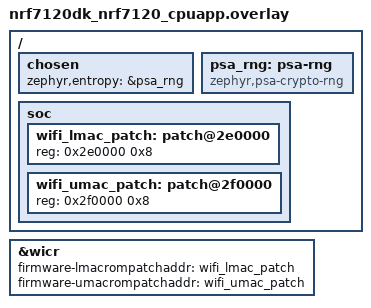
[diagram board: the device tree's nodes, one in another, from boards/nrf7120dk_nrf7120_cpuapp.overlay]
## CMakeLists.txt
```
#
# Copyright (c) 2026 Nordic Semiconductor ASA
#
# SPDX-License-Identifier: LicenseRef-Nordic-5-Clause
#

cmake_minimum_required(VERSION 3.20.0)

# The WICR LMAC/UMAC ROM patch addresses must point at the patch regions, or
# the RPU boots unpatched ROM, which has no CM2CD command handling. The dtsi
# must match the patch selected through WIFI_NRF71_PATCH_VERSION. Do not also
# pass a patch dtsi through EXTRA_DTC_OVERLAY_FILE.
list(APPEND EXTRA_DTC_OVERLAY_FILE
     ${CMAKE_CURRENT_LIST_DIR}/../../../../nrfxlib/nrf71_wifi/bins/0.1.0/nrf7120_wifi_patch.dtsi)

find_package(Zephyr REQUIRED HINTS $ENV{ZEPHYR_BASE})
project(nrf71_sr_coex)

target_sources(app PRIVATE
  src/main.c
  src/coex_tb_util.c
  src/coex_tb_params.c
  src/coex_tb_stats.c
  src/coex_tb_tests.c
)

target_include_directories(app PRIVATE
  ${ZEPHYR_NRF_MODULE_DIR}/drivers/nrf71_sr_coex/include
  ${ZEPHYR_NRF_MODULE_DIR}/drivers/wifi/nrf71/fw_if
  ${ZEPHYR_NRF_MODULE_DIR}/drivers/wifi/nrf71/osal/hw_if/hal/inc
  ${ZEPHYR_NRF_MODULE_DIR}/drivers/wifi/nrf71/inc
  ${ZEPHYR_NRF_MODULE_DIR}/drivers/wifi/nrf71/inc/common/fw_if
)
```

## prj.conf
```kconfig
# Copyright (c) 2026 Nordic Semiconductor ASA
#
# SPDX-License-Identifier: LicenseRef-Nordic-5-Clause
#

# The Wi-Fi and Short-Range coexistence driver under test.
CONFIG_NRF71_SR_COEX_DRIVER=y

# The coexistence driver sits between: the nRF71 Wi-Fi driver owns
# the FMAC transport that carries CD2CM commands to the RPU, and
# the Short-Range (for example, Bluetooth) side of the arbitration.
CONFIG_WIFI=y
CONFIG_WIFI_NM_WPA_SUPPLICANT=y
CONFIG_BT=y

# The Coexistence Manager command handling lives in the Wi-Fi ROM patch. The
# board overlay points WICR at the patch regions, so the patch must be merged
# into the flashed image.
CONFIG_WIFI_NRF71_PATCH=y

# bt_le_set_chan_map() returns -ENOTSUP unless the Controller is a central or a
# broadcaster, so the BLE bad-channel mapping test needs one of the two roles.
CONFIG_BT_CENTRAL=y

# Networking (Wi-Fi driver build dependency).
CONFIG_NETWORKING=y
CONFIG_NET_L2_ETHERNET=y
CONFIG_NET_L2_ETHERNET_MGMT=y
CONFIG_NET_MGMT=y
CONFIG_NET_MGMT_EVENT=y

CONFIG_NET_PKT_RX_COUNT=16
CONFIG_NET_PKT_TX_COUNT=16
CONFIG_NET_BUF_RX_COUNT=16
CONFIG_NET_BUF_TX_COUNT=32
CONFIG_HEAP_MEM_POOL_SIZE=230000

# IPC transport to the RPU.
CONFIG_IPC_SERVICE_BACKEND_ICMSG_WQ_ENABLE=y
CONFIG_IPC_SERVICE_BACKEND_ICMSG_WQ_STACK_SIZE=5600

# Logging. Immediate mode keeps driver log lines interleaved with the test
# bench printk output in the right order, which matters when reading a failure.
CONFIG_LOG=y
CONFIG_LOG_MODE_IMMEDIATE=y
CONFIG_NRF71_SR_COEX_DRIVER_LOG_LEVEL_DBG=y

# Keep the Wi-Fi driver debug logging off so it does not bury the test bench output.
CONFIG_WIFI_NRF71_LOG_LEVEL_DBG=n

# Set to y to open an MPC override on the Wi-Fi debug register window
# (0x48000000) so a debugger can reach the LMAC/UMAC VPRs. Useful to tell "Wi-Fi
# core never started" apart from "core runs but the ipc0 ICMsg peer never binds",
# because nrf_wifi_fmac_ver_get() is stubbed and its "booted successfully" log
# line does not touch the RPU. Disabled by default.
CONFIG_SOC_NRF71_WIFI_DAP=n

CONFIG_MAIN_STACK_SIZE=8192
```

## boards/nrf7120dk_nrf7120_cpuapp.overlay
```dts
/*
 * Copyright (c) 2026 Nordic Semiconductor ASA
 *
 * SPDX-License-Identifier: LicenseRef-Nordic-5-Clause
 */

/* Enable PSA RNG for entropy */
/ {
	chosen {
		zephyr,entropy = &psa_rng;
	};

	psa_rng: psa-rng {
		compatible = "zephyr,psa-crypto-rng";
		status = "okay";
	};
};

/*
 * The LMAC and UMAC ROM patch descriptors sit in MRAM: LMAC_APP.hex populates
 * 0x2e0000 and UMAC_APP.hex populates 0x2f0000, which is also what
 * nrfxlib/nrf71_wifi/bins/wicr.hex points the WICR patch words at.
 *
 * nrf7120_enga.dtsi instead points firmware-lmacrompatchaddr and
 * firmware-umacrompatchaddr at the ROM entry offsets (0x28080172 / 0x2818011c),
 * so wicr_setup() overwrites the flashed patch addresses at boot and the ROM
 * follows a bogus pointer, leaving the Wi-Fi core dead before IPC init.
 */
/ {
	soc {
		wifi_lmac_patch: patch@2e0000 {
			reg = <0x2e0000 0x8>;
		};

		wifi_umac_patch: patch@2f0000 {
			reg = <0x2f0000 0x8>;
		};
	};
};

&wicr {
	firmware-lmacrompatchaddr = <&wifi_lmac_patch>;
	firmware-umacrompatchaddr = <&wifi_umac_patch>;
};
```

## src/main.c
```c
/* main.c - build-only exercise of the nRF71 SR coexistence driver API */

/*
 * Copyright (c) 2026 Nordic Semiconductor ASA
 *
 * SPDX-License-Identifier: LicenseRef-Nordic-5-Clause
 */

#include <errno.h>

#include <zephyr/kernel.h>
#include <zephyr/sys/printk.h>

#include <drivers/nrf71_sr_coex/nrf71_sr_coex.h>
#include <drivers/nrf71_sr_coex/nrf71_sr_coex_sr.h>

/*
 * This test builds the standalone nRF71 SR coexistence driver together with the
 * nRF71 Wi-Fi driver and exercises the driver API contract so the driver links
 * against the Wi-Fi FMAC coexistence transport. It also registers stub
 * Short-Range driver callbacks, as the real SR driver does at boot.
 */
static int test_sr_enable(bool enable)
{
	ARG_UNUSED(enable);
	return 0;
}

static int test_sr_set_priority(const struct nrf71_sr_coex_sr_prio *prio)
{
	ARG_UNUSED(prio);
	return 0;
}

static const struct nrf71_sr_coex_sr_driver_cb test_sr_driver_cb = {
	.enable = test_sr_enable,
	.set_priority = test_sr_set_priority,
};

int main(void)
{
	const struct nrf71_sr_coex_prio prio = {
		.wifi = {
			.sw_request = {10, 5, 1},
			.hp_rx = {20, 15, 1},
			.hp_tx = {25, 20, 1},
			.lp_rx = {140, 120, 3},
			.lp_tx = {160, 145, 3},
			.level = 5,
		},
		.sr = {
			.rx = {30, 25, 1},
			.tx = {40, 30, 2},
			.rx_critical = {5, 0, 1},
			.tx_critical = {5, 0, 1},
			.level = 5,
		},
	};
	const struct nrf71_sr_coex_user_params user = {
		.sr_rx_prot_ps_listen2inactive = 100,
		.sr_rx_prot_ps_inactive2listen = 100,
		.sr_rx_prot_calib_listen2inactive = 100,
		.sr_rx_prot_calib_inactive2listen = 100,
		.wifi_scan_prot = 100,
		.wifi_beacon_prot = 100,
		.wifi_conn_prot = 100,
		.wifi_calib_prot = 100,
		.ant_alloc = NRF71_SR_COEX_ANT_ALLOC_DYNAMIC,
	};
	const struct nrf71_sr_coex_cfg cfg = {
		.antenna = NRF71_SR_COEX_ANTENNA_SHARED,
		.prio = &prio,
		.user = &user,
	};
	int ret;

	ret = nrf71_sr_coex_sr_register(&test_sr_driver_cb);
	if (ret != 0) {
		printk("SR driver callback registration failed: %d\n", ret);
	}

	(void)nrf71_sr_coex_sr_power_notify(NRF71_SR_COEX_SR_POWERED_UP_READY);
	(void)nrf71_sr_coex_sr_power_notify(NRF71_SR_COEX_SR_PREPARE_POWER_DOWN);

	/*
	 * The priority ranges and user params are stored whether Wi-Fi is up or
	 * not, and applied to the CM every time Wi-Fi comes up, so this succeeds.
	 */
	ret = nrf71_sr_coex_init(&cfg);
	printk("nrf71_sr_coex_init(): %d (expected 0)\n", ret);

	/* The configuration can be set only once. */
	ret = nrf71_sr_coex_init(&cfg);
	printk("nrf71_sr_coex_init() twice: %d (expected %d)\n", ret, -EALREADY);

	printk("nRF71 SR coexistence driver built\n");

	return 0;
}
```

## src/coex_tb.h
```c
/*
 * Copyright (c) 2026 Nordic Semiconductor ASA
 *
 * SPDX-License-Identifier: LicenseRef-Nordic-5-Clause
 */

/** @file
 * @brief nRF71 SR coexistence driver test bench configuration.
 *
 * The bench exercises the driver's interfaces:
 *
 *   1. Application / configuration APIs (coex_cd_*). These turn into CD2CM commands.
 *   2. Wi-Fi driver to CD notifications (coex_cd_wifi_power_notify, which drives
 *      the driver's CM bring-up and teardown sequence, and
 *      coex_cd_wifi_channel_notify, which drives BLE bad-channel mapping).
 *   3. SR driver to CD notifications (coex_cd_sr_power_notify) and the SR driver
 *      callbacks the SR driver registers through coex_cd_register_sr_driver_cb().
 *   4. Direct COEXC hardware programming which is register access rather than messaging.
 *
 * TEST ORDER MATTERS
 * ------------------
 * The steps below are not independent. COEXC hardware must be programmed before
 * CM arbitration has any effect, and both radios must report "powered up" before
 * CM-dependent steps run.
 *
 * CM bring-up: coex_tb_prepare() calls coex_cd_wifi_power_notify() automatically
 * when any CM-dependent test is enabled and COEX_TB_TEST_INIT_AND_ENABLE is not. Enable
 * COEX_TB_TEST_INIT_AND_ENABLE only when you want to exercise that notification
 * API explicitly.
 */

#ifndef COEX_TB_H__
#define COEX_TB_H__

#include <stdint.h>

#include <nrf71_coex_if.h>
#include <nrf71_sr_coex_api.h>

/* Timing (all values in milliseconds) */
/** Pause after a command whose effect needs a moment to be observable. */
#define COEX_TB_CMD_WAIT_MS            500U

/** Final drain time before the verdict is printed. */
#define COEX_TB_FINAL_WAIT_MS          2000U

/** Interval between polls while waiting for the Wi-Fi FMAC transport. */
#define COEX_TB_POLL_INTERVAL_MS       100U

/** Consecutive ready polls required before the transport is trusted. */
#define COEX_TB_TRANSPORT_STABLE_POLLS 5U

/** Extra time after transport looks ready, before CM commands (RPU/VIF settle). */
#define COEX_TB_RPU_SETTLE_MS          3000U

/** How long to wait for Wi-Fi-driver CM bring-up before retrying from the bench. */
#define COEX_TB_CM_BRINGUP_TIMEOUT_MS  30000U

/** Give up waiting for the Wi-Fi transport after this long. */
#define COEX_TB_TRANSPORT_TIMEOUT_MS   60000U

/*
 * ---------------------------------------------------------------------------
 * Buffer sizes and blob layout
 * ---------------------------------------------------------------------------
 */

/**
 * Size of the CD2CM_UPDATE_COEX_PARAMS blob buffer.
 *
 * Taken straight from the driver's advertised limit, CD2CM_COEX_PARAMS_MAX_BLOB_LEN
 * in nrf71_sr_coex_api.h.
 */
#define COEX_TB_COEX_PARAMS_BLOB_MAX CD2CM_COEX_PARAMS_MAX_BLOB_LEN

/**
 * Byte offset of the shared-LNA-switch control field inside the decoded
 * NRF_COEX_PARAMS blob.
 */
#define COEX_TB_BLOB_LNASW_OFFSET 44U

/**
 * Print the Wi-Fi core bring-up state (WICR words and ipc0 regions) before the test
 * run starts. Diagnostic for a Wi-Fi transport that never comes up. Comment out to
 * skip it.
 */
#define COEX_TB_DUMP_WIFI_BRINGUP_STATE

/*
 * ---------------------------------------------------------------------------
 * Test selection: comment out a line to skip that step
 * ---------------------------------------------------------------------------
 */

/** Program the COEXC registers (direct register writes, no CM command). */
#define COEX_TB_TEST_CONFIGURE_COEXC

/** Reject bad arguments without disturbing CM state. Runs early on purpose. */
#define COEX_TB_TEST_NEGATIVE_ARGS

/** Report both radios as powered up, which triggers full CM configuration. */
#define COEX_TB_TEST_INIT_AND_ENABLE

/** Send Wi-Fi and SR PTI priority ranges. */
#define COEX_TB_TEST_SET_PRIORITY_RANGES

/** Send protection probabilities and the shared-antenna mode. */
#define COEX_TB_TEST_UPDATE_COEX_USER_PARAMS

/** Send the built-in coexistence parameter blob. */
#define COEX_TB_TEST_UPDATE_COEX_PARAMETERS

/** Toggle coexistence off and on in the CM. */
#define COEX_TB_TEST_ENABLE_COEXISTENCE

/**
 * Number of enable/disable iterations.
 *
 * Iteration 1 enables, iteration 2 disables, and so on. Use an even count to
 * exercise both directions; the test re-enables coexistence when it finishes
 * regardless, so later steps always start from a known state.
 */
#define COEX_TB_NUM_ENABLE_COEX_TESTS 1U

/** Walk the shared-antenna allocation modes (dynamic, static Wi-Fi, static SR). */
#define COEX_TB_TEST_FORCE_ANTENNA_ALLOC

/** Walk the shared-LNA-switch control modes. */
#define COEX_TB_TEST_FORCE_LNASW_ALLOC

/** Map a connected-state Wi-Fi channel onto the BLE data-channel classification. */
#define COEX_TB_TEST_BLE_CHAN_MAP

/** Read the CM counters and cross-check them. Keep this last. */
#define COEX_TB_TEST_GET_CM_STATS

/*
 * At least one enabled step needs the CM over the Wi-Fi FMAC path.
 * coex_tb_prepare() brings the CM up automatically before the test runner unless
 * COEX_TB_TEST_INIT_AND_ENABLE is enabled (that step performs bring-up itself).
 */
#if defined(COEX_TB_TEST_SET_PRIORITY_RANGES) ||                                        \
	defined(COEX_TB_TEST_UPDATE_COEX_USER_PARAMS) ||                                    \
	defined(COEX_TB_TEST_UPDATE_COEX_PARAMETERS) ||                                     \
	defined(COEX_TB_TEST_ENABLE_COEXISTENCE) ||                                         \
	defined(COEX_TB_TEST_FORCE_ANTENNA_ALLOC) ||                                        \
	defined(COEX_TB_TEST_FORCE_LNASW_ALLOC) ||                                          \
	defined(COEX_TB_TEST_GET_CM_STATS)
#define COEX_TB_NEEDS_CM_BRINGUP
#endif

/*
 * ---------------------------------------------------------------------------
 * BLE bad-channel mapping test parameters
 * ---------------------------------------------------------------------------
 * The worked example from both specifications: Wi-Fi channel 6 at 20 MHz with a
 * 3 MHz guard band guards 2424 to 2450 MHz, which makes BLE data channels 10
 * through 22 bad and leaves the rest available.
 */

/** Wi-Fi channel 6 centre frequency, in MHz. */
#define COEX_TB_WIFI_CH6_CENTER_MHZ    2437U

/** Wi-Fi channel 6 bandwidth, in MHz. */
#define COEX_TB_WIFI_CH6_BANDWIDTH_MHZ 20U

/** Guard band applied either side of channel 6, in MHz. */
#define COEX_TB_WIFI_CH6_GUARD_MHZ     3U

/** A 5 GHz centre frequency, which must leave every BLE data channel available. */
#define COEX_TB_WIFI_5G_CENTER_MHZ     5180U

/** Bandwidth used for the 5 GHz and 6 GHz cases, in MHz. */
#define COEX_TB_WIFI_5G_BANDWIDTH_MHZ  80U

/** A 6 GHz centre frequency. */
#define COEX_TB_WIFI_6G_CENTER_MHZ     5955U

/** A guard band above the accepted maximum, used to test rejection. */
#define COEX_TB_WIFI_BAD_GUARD_MHZ     9U

/** A deliberately out-of-range coex_wifi_band_t, used to test rejection. */
#define COEX_TB_WIFI_BAD_BAND          7

#endif /* COEX_TB_H__ */
```

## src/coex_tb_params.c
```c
/*
 * Copyright (c) 2026 Nordic Semiconductor ASA
 *
 * SPDX-License-Identifier: LicenseRef-Nordic-5-Clause
 */

/** @file
 * @brief Parameter builders for the coexistence driver APIs under test.
 */

#include <errno.h>
#include <string.h>

#include <zephyr/sys/util.h>

#include "coex_tb.h"
#include "coex_tb_params.h"

void coex_tb_params_priority_ranges(struct coex_wifi_priority_range_t *wifi_range,
				    struct coex_sr_priority_range_t *sr_range)
{
	if (wifi_range != NULL) {
		/* Wi-Fi has four hardware clients plus a software-request range. */
		*wifi_range = (struct coex_wifi_priority_range_t){
			.sw_request_priority_range = {10, 5, 1},
			.client0_ccconf_pti_range = {20, 15, 1},   /* high-prio Wi-Fi Rx */
			.client1_ccconf_pti_range = {25, 20, 1},   /* high-prio Wi-Fi Tx */
			.client2_ccconf_pti_range = {140, 120, 3}, /* low-prio Wi-Fi Rx */
			.client3_ccconf_pti_range = {160, 145, 3}, /* low-prio Wi-Fi Tx */
			.hw_client_priority_level = 5,
		};
	}

	if (sr_range != NULL) {
		/*
		 * SR has a normal and a "critical" range for both Rx and Tx.
		 * The critical ranges sit at lower PTI numbers than the Wi-Fi ranges
		 * so that time-critical SR traffic can win the antenna.
		 */
		*sr_range = (struct coex_sr_priority_range_t){
			.sr_rx_client_ccconf_pti_range = {30, 25, 1},
			.sr_tx_client_ccconf_pti_range = {40, 30, 2},
			.client_priority_level = 5,
			.sr_rx_client_critical_ccconf_pti_range = {5, 0, 1},
			.sr_tx_client_critical_ccconf_pti_range = {5, 0, 1},
		};
	}
}

void coex_tb_params_user_params(struct coex_user_params_t *user_params)
{
	/* Dynamic antenna allocation, matching the coexistence driver default. */
	coex_tb_params_user_params_ant_alloc(user_params, ANT_ALLOC_DYNAMIC);
}

void coex_tb_params_user_params_ant_alloc(struct coex_user_params_t *user_params,
					  enum antenna_allocation_t ant_mode)
{
	if (user_params == NULL) {
		return;
	}

	/*
	 * All probabilities are percentages. 100 means "always protect this
	 * activity". message_id is part of the payload as well as the command
	 * header, so it is set here too.
	 */
	*user_params = (struct coex_user_params_t){
		.message_id = CD2CM_UPDATE_COEX_USER_PARAMS,
		.listen2inactive_sr_rx_prot_prob_ps = 100,
		.inactive2listen_sr_rx_prot_prob_ps = 100,
		.inactive2listen_sr_rx_prot_prob_calib = 100,
		.listen2inactive_sr_rx_prot_prob_calib = 100,
		.wifi_scan_puncture_info = {.wifi_scan_prot_prob = 100},
		.wifi_beacon_prot_prob = 100,
		.wifi_conn_prot_prob = 100,
		.wifi_calib_prot_prob = 100,
		.shared_ant_control = ant_mode,
	};
}

int coex_tb_params_default_coex_blob(uint8_t *blob, size_t blob_size, size_t *out_len)
{
	size_t decoded;

	if ((blob == NULL) || (out_len == NULL)) {
		return -EINVAL;
	}

	/*
	 * hex2bin() returns the number of bytes written, or 0 if the string is
	 * malformed or does not fit in blob_size. The return type is unsigned,
	 * so 0 is the only failure indication.
	 */
	decoded = hex2bin(NRF_COEX_PARAMS, strlen(NRF_COEX_PARAMS), blob, blob_size);
	if (decoded == 0U) {
		return -EINVAL;
	}

	*out_len = decoded;
	return 0;
}

int coex_tb_params_coex_blob_lna(uint8_t lna_control, uint8_t *blob, size_t blob_size,
				 size_t *out_len, uint8_t *out_original)
{
	int ret;

	ret = coex_tb_params_default_coex_blob(blob, blob_size, out_len);
	if (ret != 0) {
		return ret;
	}

	/* Offset must be inside the decoded blob, not just inside the buffer. */
	if (*out_len <= COEX_TB_BLOB_LNASW_OFFSET) {
		return -EINVAL;
	}

	if (out_original != NULL) {
		*out_original = blob[COEX_TB_BLOB_LNASW_OFFSET];
	}

	blob[COEX_TB_BLOB_LNASW_OFFSET] = lna_control;
	return 0;
}

void coex_tb_params_wifi_channel(struct coex_wifi_channel_info_t *channel_info, int band,
				 unsigned short center_mhz, unsigned short bandwidth_mhz,
				 unsigned char guard_mhz)
{
	if (channel_info == NULL) {
		return;
	}

	*channel_info = (struct coex_wifi_channel_info_t){
		.band = (enum coex_wifi_band_t)band,
		.center_frequency_mhz = center_mhz,
		.bandwidth_mhz = bandwidth_mhz,
		.guard_band_mhz = guard_mhz,
	};
}
```

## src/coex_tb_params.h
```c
/*
 * Copyright (c) 2026 Nordic Semiconductor ASA
 *
 * SPDX-License-Identifier: LicenseRef-Nordic-5-Clause
 */

/** @file
 * @brief Parameter builders for the Coexistence Driver (CD) APIs under test.
 */

#ifndef COEX_TB_PARAMS_H__
#define COEX_TB_PARAMS_H__

#include <stddef.h>
#include <stdint.h>

#include <nrf71_coex_if.h>
#include <nrf71_sr_coex_api.h>

/**
 * Fill in Wi-Fi and SR priority ranges.
 *
 * A "PTI range" is {start, end, step}. Lower numbers mean higher priority, so
 * start is the lowest-priority value of the range and end the highest. The CM
 * uses these to decide which radio wins when both want the antenna.
 */
void coex_tb_params_priority_ranges(struct coex_wifi_priority_range_t *wifi_range,
				    struct coex_sr_priority_range_t *sr_range);

/** Fill in the default user parameters. */
void coex_tb_params_user_params(struct coex_user_params_t *user_params);

/**
 * Same as coex_tb_params_user_params() but with an explicit shared-antenna mode.
 *
 * @param ant_mode ANT_ALLOC_DYNAMIC lets the CM arbitrate; ANT_ALLOC_STATIC_WIFI
 *                 and ANT_ALLOC_STATIC_SR pin the antenna to one radio.
 */
void coex_tb_params_user_params_ant_alloc(struct coex_user_params_t *user_params,
					  enum antenna_allocation_t ant_mode);

/**
 * Decode the built-in NRF_COEX_PARAMS hex string into a binary blob.
 *
 * NRF_COEX_PARAMS is a compile-time hex string of CM tuning values. The CM
 * wants the binary form, so it is decoded here.
 *
 * @param blob      Destination buffer.
 * @param blob_size Size of blob; must be at least half the hex string length.
 * @param out_len   Out: number of decoded bytes.
 *
 * @retval 0       Decoded successfully.
 * @retval -EINVAL NULL argument, or the hex string did not fit / was malformed.
 */
int coex_tb_params_default_coex_blob(uint8_t *blob, size_t blob_size, size_t *out_len);

/**
 * Build a coex-params blob with the shared-LNA-switch control byte replaced.
 *
 * Starts from the default blob and patches one byte at
 * COEX_TB_BLOB_LNASW_OFFSET.
 *
 * @param lna_control  0 = dynamic, 1 = statically enabled, 2 = statically disabled.
 * @param out_original Out: byte value before patching, for logging. May be NULL.
 *
 * @retval 0       Blob built.
 * @retval -EINVAL NULL argument, or the blob is too short to hold the offset.
 */
int coex_tb_params_coex_blob_lna(uint8_t lna_control, uint8_t *blob, size_t blob_size,
				 size_t *out_len, uint8_t *out_original);

/**
 * Fill in a connected-state Wi-Fi channel description, as the Wi-Fi driver would.
 *
 * @param band          Operating band. Passed as int so a deliberately invalid
 *                      value can be used to test rejection.
 * @param center_mhz    Channel centre frequency in MHz.
 * @param bandwidth_mhz Channel bandwidth in MHz.
 * @param guard_mhz     Guard band applied either side of the channel, in MHz.
 */
void coex_tb_params_wifi_channel(struct coex_wifi_channel_info_t *channel_info, int band,
				 unsigned short center_mhz, unsigned short bandwidth_mhz,
				 unsigned char guard_mhz);

#endif /* COEX_TB_PARAMS_H__ */
```

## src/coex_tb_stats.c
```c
/*
 * Copyright (c) 2026 Nordic Semiconductor ASA
 *
 * SPDX-License-Identifier: LicenseRef-Nordic-5-Clause
 */

/** @file
 * @brief CM statistics printing and consistency checking.
 */

#include <stdbool.h>

#include <zephyr/sys/printk.h>

#include "coex_tb_stats.h"
#include "coex_tb.h"

/**
 * Print one consistency check and report whether it failed.
 *
 * @return 1 if the check failed, 0 if it passed, so callers can sum the result.
 */
static unsigned int tb_check(unsigned int *check_num, bool pass, const char *what)
{
	(*check_num)++;
	printk("  [CHECK %02u] %-56s %s\n", *check_num, what, pass ? "PASS" : "FAIL");

	return pass ? 0U : 1U;
}

/** Per-event counters that only patched CM firmware reports. */
static void coex_tb_print_patch_stats(const struct cm_fsm_patch_stats_t *p)
{
	printk("\n==================== Patch Command Counts (cm_fsm_patch.c)\n");
	printk("  cm_coex_process_cmd_cnt_patch:      %u\n", p->cm_coex_process_cmd_cnt_patch);
	printk("  cmd_update_coex_params_cnt_patch:   %u\n", p->cmd_update_coex_params_cnt_patch);
	printk("  cmd_update_user_params_cnt_patch:   %u\n", p->cmd_update_user_params_cnt_patch);
	printk("  cmd_enable_coex_cnt_patch:          %u\n", p->cmd_enable_coex_cnt_patch);
	printk("  cmd_allocate_ppw_cnt_patch:         %u\n", p->cmd_allocate_ppw_cnt_patch);
	printk("  cmd_set_pti_ranges_cnt_patch:       %u\n", p->cmd_set_pti_ranges_cnt_patch);
	printk("  cmd_get_stats_cnt_patch:            %u\n", p->cmd_get_stats_cnt_patch);
	printk("  cmd_wifi_sw_client_req_cnt_patch:   %u\n", p->cmd_wifi_sw_client_req_cnt_patch);
}

static void coex_tb_print_stats(const struct cm_stats_t *s,
				const struct cm_fsm_patch_stats_t *patch_stats)
{
	printk("\n==================== PPW Statistics\n");
	printk("  init_count:                %u\n", s->init_count);
	printk("  ppw_start_msgs_cnt:        %u\n", s->ppw_start_msgs_cnt);
	printk("  ppw_stop_msgs_cnt:         %u\n", s->ppw_stop_msgs_cnt);
	printk("  ppw_stop_timeout_cnt:      %u\n", s->ppw_stop_timeout_cnt);
	printk("  num_wifi_pti_windows:      %u\n", s->num_wifi_pti_windows);
	printk("  num_sr_pti_windows:        %u\n", s->num_sr_pti_windows);
	printk("  wifi_ccconf_wifi_window:   %u\n", s->wifi_ccconf_wifi_window);
	printk("  wifi_ccconf_sr_window:     %u\n", s->wifi_ccconf_sr_window);
	printk("  ppw_invalid_params_cnt:    %u\n", s->ppw_invalid_params_cnt);
	printk("  ppw_invalid_request_cnt:   %u\n", s->ppw_invalid_request_cnt);

	printk("\n==================== Band Select\n");
	printk("  cfg_band_sel_5g_cnt:       %u\n", s->cfg_band_sel_5g_cnt);
	printk("  cfg_band_sel_2pt4g_cnt:    %u\n", s->cfg_band_sel_2pt4g_cnt);

	printk("\n==================== Wi-Fi SW Client Aggregate\n");
	printk("  wifi_sw_client_req_cnt:                        %u\n", s->wifi_sw_client_req_cnt);
	printk("  wifi_sw_client_rel_cnt:                        %u\n", s->wifi_sw_client_rel_cnt);
	printk("  wifi_sw_client_gnt_cnt:                        %u\n", s->wifi_sw_client_gnt_cnt);
	printk("  wifi_sw_client_rel_timeout_cnt:                %u\n",
	       s->wifi_sw_client_rel_timeout_cnt);
	printk("  wifi_sw_client_req_non2pt4g_band_cnt:          %u\n",
	       s->wifi_sw_client_req_non2pt4g_band_cnt);
	printk("  wifi_sw_client_req_2pt4g_band_cnt:             %u\n",
	       s->wifi_sw_client_req_2pt4g_band_cnt);
	printk("  wifi_sw_client_decison_in_favour_cnt_2pt4g:    %u\n",
	       s->wifi_sw_client_decison_in_favour_cnt_2pt4g);
	printk("  wifi_sw_client_decison_not_in_favour_cnt_2pt4g:%u\n",
	       s->wifi_sw_client_decison_not_in_favour_cnt_2pt4g);
	printk("  wifi_sw_client_no_gnt_cnt_2pt4g:               %u\n",
	       s->wifi_sw_client_no_gnt_cnt_2pt4g);
	printk("  wifi_sw_client_no_gnt_cnt_non_2pt4g:           %u\n",
	       s->wifi_sw_client_no_gnt_cnt_non_2pt4g);
	printk("  wifi_sw_client_rel_cnt_2pt4g:                  %u\n",
	       s->wifi_sw_client_rel_cnt_2pt4g);
	printk("  wifi_sw_client_rel_cnt_non_2pt4g:              %u\n",
	       s->wifi_sw_client_rel_cnt_non_2pt4g);
	printk("  wifi_sw_client_gnt_cnt_2pt4g:                  %u\n",
	       s->wifi_sw_client_gnt_cnt_2pt4g);
	printk("  wifi_sw_client_gnt_cnt_non_2pt4g:              %u\n",
	       s->wifi_sw_client_gnt_cnt_non_2pt4g);

	printk("\n==================== Wi-Fi Per-Client Req/Rel/Gnt\n");
	printk("  wifi_beacon_rx_req_cnt:    %u\n", s->wifi_beacon_rx_req_cnt);
	printk("  wifi_conn_req_cnt:         %u\n", s->wifi_conn_req_cnt);
	printk("  wifi_calib_req_cnt:        %u\n", s->wifi_calib_req_cnt);
	printk("  wifi_scan_req_cnt:         %u\n", s->wifi_scan_req_cnt);
	printk("  wifi_beacon_rx_rel_cnt:    %u\n", s->wifi_beacon_rx_rel_cnt);
	printk("  wifi_conn_rel_cnt:         %u\n", s->wifi_conn_rel_cnt);
	printk("  wifi_calib_rel_cnt:        %u\n", s->wifi_calib_rel_cnt);
	printk("  wifi_scan_rel_cnt:         %u\n", s->wifi_scan_rel_cnt);
	printk("  wifi_beacon_rx_gnt_cnt:    %u\n", s->wifi_beacon_rx_gnt_cnt);
	printk("  wifi_conn_gnt_cnt:         %u\n", s->wifi_conn_gnt_cnt);
	printk("  wifi_calib_gnt_cnt:        %u\n", s->wifi_calib_gnt_cnt);
	printk("  wifi_scan_gnt_cnt:         %u\n", s->wifi_scan_gnt_cnt);
	printk("  wifi_beacon_rx_no_gnt_cnt: %u\n", s->wifi_beacon_rx_no_gnt_cnt);
	printk("  wifi_conn_no_gnt_cnt:      %u\n", s->wifi_conn_no_gnt_cnt);
	printk("  wifi_calib_no_gnt_cnt:     %u\n", s->wifi_calib_no_gnt_cnt);
	printk("  wifi_scan_no_gnt_cnt:      %u\n", s->wifi_scan_no_gnt_cnt);
	printk("  wifi_beacon_rx_rel_to_cnt: %u\n", s->wifi_beacon_rx_rel_to_cnt);
	printk("  wifi_conn_rel_to_cnt:      %u\n", s->wifi_conn_rel_to_cnt);
	printk("  wifi_calib_rel_to_cnt:     %u\n", s->wifi_calib_rel_to_cnt);
	printk("  wifi_scan_rel_to_cnt:      %u\n", s->wifi_scan_rel_to_cnt);

	printk("\n==================== SR Rx Protection\n");
	printk("  sr_rx_prot_success_cnt_2pt4g:                  %u\n",
	       s->sr_rx_prot_success_cnt_2pt4g);
	printk("  sr_rx_prot_fail_cnt_2pt4g:                     %u\n",
	       s->sr_rx_prot_fail_cnt_2pt4g);
	printk("  sr_rx_prot_success_cnt_non_2pt4g:              %u\n",
	       s->sr_rx_prot_success_cnt_non_2pt4g);
	printk("  sr_rx_prot_fail_cnt_non_2pt4g:                 %u\n",
	       s->sr_rx_prot_fail_cnt_non_2pt4g);
	printk("  sr_rx_prot_inact2listen_ps_cnt_2pt4g:          %u\n",
	       s->sr_rx_prot_inact2listen_ps_cnt_2pt4g);
	printk("  sr_rx_prot_listen2inact_ps_cnt_2pt4g:          %u\n",
	       s->sr_rx_prot_listen2inact_ps_cnt_2pt4g);
	printk("  sr_rx_prot_inact2listen_calib_cnt_2pt4g:       %u\n",
	       s->sr_rx_prot_inact2listen_calib_cnt_2pt4g);
	printk("  sr_rx_prot_listen2inact_calib_cnt_2pt4g:       %u\n",
	       s->sr_rx_prot_listen2inact_calib_cnt_2pt4g);
	printk("  sr_rx_prot_inact2listen_ps_cnt_non_2pt4g:      %u\n",
	       s->sr_rx_prot_inact2listen_ps_cnt_non_2pt4g);
	printk("  sr_rx_prot_listen2inact_ps_cnt_non_2pt4g:      %u\n",
	       s->sr_rx_prot_listen2inact_ps_cnt_non_2pt4g);
	printk("  sr_rx_prot_inact2listen_calib_cnt_non_2pt4g:   %u\n",
	       s->sr_rx_prot_inact2listen_calib_cnt_non_2pt4g);
	printk("  sr_rx_prot_listen2inact_calib_cnt_non_2pt4g:   %u\n",
	       s->sr_rx_prot_listen2inact_calib_cnt_non_2pt4g);
	printk("  sr_rx_prot_2pt4g_band_cnt:                     %u\n",
	       s->sr_rx_prot_2pt4g_band_cnt);
	printk("  sr_rx_prot_non2pt4g_band_cnt:                  %u\n",
	       s->sr_rx_prot_non2pt4g_band_cnt);
	printk("  sr_rx_prot_force_wifi_cnt_2pt4g:               %u\n",
	       s->sr_rx_prot_force_wifi_cnt_2pt4g);

	printk("\n==================== Coex Enable/Disable\n");
	printk("  coex_enable_cnt:           %u\n", s->coex_enable_cnt);
	printk("  coex_disable_cnt:          %u\n", s->coex_disable_cnt);

	printk("\n==================== ANTSWC Configuration\n");
	printk("  antswc_inhibit_cfg_cnt:          %u\n", s->antswc_inhibit_cfg_cnt);
	printk("  antswc_anten_override_cfg_cnt:   %u\n", s->antswc_anten_override_cfg_cnt);
	printk("  antswc_pa_override_cfg_cnt:      %u\n", s->antswc_pa_override_cfg_cnt);
	printk("  antswc_lnasw_override_cfg_cnt:   %u\n", s->antswc_lnasw_override_cfg_cnt);

	printk("\n==================== CCCONF\n");
	printk("  wifi_ccconf_save_cnt:      %u\n", s->wifi_ccconf_save_cnt);
	printk("  wifi_ccconf_restore_cnt:   %u\n", s->wifi_ccconf_restore_cnt);

	printk("\n==================== Command Counts\n");
	printk("  cmd_update_coex_params_cnt:   %u\n", s->cmd_update_coex_params_cnt);
	printk("  cmd_update_user_params_cnt:   %u\n", s->cmd_update_user_params_cnt);
	printk("  cmd_enable_coex_cnt:          %u\n", s->cmd_enable_coex_cnt);
	printk("  cmd_allocate_ppw_cnt:         %u\n", s->cmd_allocate_ppw_cnt);
	printk("  cmd_set_pti_ranges_cnt:       %u\n", s->cmd_set_pti_ranges_cnt);
	printk("  cmd_sw_client_req_cnt:        %u\n", s->cmd_sw_client_req_cnt);
	printk("  cmd_get_stats_cnt:            %u\n", s->cmd_get_stats_cnt);

	printk("\n==================== Events\n");
	printk("  stats_event_to_host_cnt:           %u\n", s->stats_event_to_host_cnt);
	if (patch_stats != NULL) {
		printk("  coex_params_event_to_host_cnt:     %u\n",
		       patch_stats->coex_params_event_to_host_cnt);
		printk("  user_params_event_to_host_cnt:     %u\n",
		       patch_stats->user_params_event_to_host_cnt);
		printk("  enable_coex_event_to_host_cnt:     %u\n",
		       patch_stats->enable_coex_event_to_host_cnt);
		printk("  allocate_ppw_event_to_host_cnt:    %u\n",
		       patch_stats->allocate_ppw_event_to_host_cnt);
		printk("  set_pti_ranges_event_to_host_cnt:  %u\n",
		       patch_stats->set_pti_ranges_event_to_host_cnt);
		printk("  wifi_sw_client_event_to_host_cnt:  %u\n",
		       patch_stats->wifi_sw_client_event_to_host_cnt);
	} else {
		printk("  sw_client_event_to_host_cnt:       %u\n",
		       s->sw_client_event_to_host_cnt);
		printk("  (patch per-event counters require cm_fsm_patch_stats_t payload)\n");
	}

	/*
	 * These should all be zero. A non-zero value means the CM rejected
	 * something the test bench (or the driver) sent it.
	 */
	printk("\n==================== Error Counts\n");
	printk("  cd2cm_null_cmd_buf_cnt:                  %u\n", s->cd2cm_null_cmd_buf_cnt);
	printk("  cd2cm_invalid_msg_id_cnt:                %u\n", s->cd2cm_invalid_msg_id_cnt);
	printk("  coex_params_buf_error:                   %u\n", s->coex_params_buf_error);
	printk("  user_params_buf_error:                   %u\n", s->user_params_buf_error);
	printk("  en_coex_buf_error:                       %u\n", s->en_coex_buf_error);
	printk("  ppw_buf_error:                           %u\n", s->ppw_buf_error);
	printk("  set_pti_ranges_buf_error:                %u\n", s->set_pti_ranges_buf_error);
	printk("  sw_client_req_buf_error:                 %u\n", s->sw_client_req_buf_error);
	printk("  event_buf_unavailable_cnt:               %u\n", s->event_buf_unavailable_cnt);
	printk("  unknown_event_to_host:                   %u\n", s->unknown_event_to_host);
	printk("  wifi_wrong_sw_client_id_cnt:             %u\n", s->wifi_wrong_sw_client_id_cnt);
	printk("  wifi_wrong_sw_client_request_type_cnt:   %u\n",
	       s->wifi_wrong_sw_client_request_type_cnt);
	printk("  wrong_antswc_ctrl_type_cnt:              %u\n", s->wrong_antswc_ctrl_type_cnt);
	printk("  wrong_wifi_hw_client_pti_level_cnt:      %u\n",
	       s->wrong_wifi_hw_client_pti_level_cnt);
	printk("  wrong_input_populate_pti_cnt:            %u\n", s->wrong_input_populate_pti_cnt);
	printk("  wrong_sr_rx_prot_scenario_cnt:           %u\n",
	       s->wrong_sr_rx_prot_scenario_cnt);
	printk("  wrong_sr_rx_prot_perc_prob_cnt:          %u\n",
	       s->wrong_sr_rx_prot_perc_prob_cnt);
	printk("  wrong_wifi_sw_client_id_cnt:             %u\n", s->wrong_wifi_sw_client_id_cnt);
	printk("  wrong_wifi_sw_client_perc_prob_cnt:      %u\n",
	       s->wrong_wifi_sw_client_perc_prob_cnt);
	printk("  zero_ppw_win_duration_cnt:               %u\n", s->zero_ppw_win_duration_cnt);
	printk("  zero_ppw_timeout_cnt:                    %u\n", s->zero_ppw_timeout_cnt);
}

/**
 * Cross-check the CM counters against each other.
 *
 * Every check here is an identity that must hold regardless of what the test
 * bench did, so a failure points at the CM's bookkeeping rather than at the
 * test sequence.
 *
 * @return Number of failed checks.
 */
static unsigned int coex_tb_validate_stats(const struct cm_stats_t *s)
{
	unsigned int check_num = 0U;
	unsigned int failures = 0U;

	printk("\n==================== Validation Checks\n");

	/* Every request eventually ends either in an explicit release or a timeout. */
	failures += tb_check(&check_num,
			     s->wifi_sw_client_req_cnt ==
				     s->wifi_sw_client_rel_cnt +
					     s->wifi_sw_client_rel_timeout_cnt,
			     "Wi-Fi SW req == rel + rel_timeout");

	/* Every request was counted in exactly one band bucket. */
	failures += tb_check(&check_num,
			     s->wifi_sw_client_req_cnt ==
				     s->wifi_sw_client_req_non2pt4g_band_cnt +
					     s->wifi_sw_client_req_2pt4g_band_cnt,
			     "Wi-Fi SW req == non2pt4g_band + 2pt4g_band");

	/* Every request was either granted or lost the 2.4 GHz arbitration. */
	failures += tb_check(&check_num,
			     s->wifi_sw_client_req_cnt ==
				     s->wifi_sw_client_gnt_cnt +
					     s->wifi_sw_client_decison_not_in_favour_cnt_2pt4g,
			     "Wi-Fi SW req == gnt + not_in_favour_2pt4g");

	/* Grants come from non-2.4 GHz (no contention) plus won 2.4 GHz decisions. */
	failures += tb_check(&check_num,
			     s->wifi_sw_client_gnt_cnt ==
				     s->wifi_sw_client_req_non2pt4g_band_cnt +
					     s->wifi_sw_client_decison_in_favour_cnt_2pt4g,
			     "Wi-Fi SW gnt == non2pt4g_band + in_favour_2pt4g");

	/* Aggregate counters must equal the sum over the four Wi-Fi client types. */
	failures += tb_check(&check_num,
			     s->wifi_sw_client_req_cnt ==
				     s->wifi_beacon_rx_req_cnt + s->wifi_conn_req_cnt +
					     s->wifi_calib_req_cnt + s->wifi_scan_req_cnt,
			     "Wi-Fi SW req == sum(per-client req)");

	failures += tb_check(&check_num,
			     s->wifi_sw_client_rel_cnt ==
				     s->wifi_beacon_rx_rel_cnt + s->wifi_conn_rel_cnt +
					     s->wifi_calib_rel_cnt + s->wifi_scan_rel_cnt,
			     "Wi-Fi SW rel == sum(per-client rel)");

	failures += tb_check(&check_num,
			     s->wifi_sw_client_gnt_cnt ==
				     s->wifi_beacon_rx_gnt_cnt + s->wifi_conn_gnt_cnt +
					     s->wifi_calib_gnt_cnt + s->wifi_scan_gnt_cnt,
			     "Wi-Fi SW gnt == sum(per-client gnt)");

	failures += tb_check(&check_num,
			     s->wifi_sw_client_rel_timeout_cnt ==
				     s->wifi_beacon_rx_rel_to_cnt + s->wifi_conn_rel_to_cnt +
					     s->wifi_calib_rel_to_cnt + s->wifi_scan_rel_to_cnt,
			     "Wi-Fi SW rel_timeout == sum(per-client rel_to)");

	/* The same request/grant and request/release identities, per client type. */
	failures += tb_check(&check_num,
			     s->wifi_beacon_rx_req_cnt ==
				     s->wifi_beacon_rx_gnt_cnt + s->wifi_beacon_rx_no_gnt_cnt,
			     "Wi-Fi beacon_rx: req == gnt + no_gnt");

	failures += tb_check(&check_num,
			     s->wifi_beacon_rx_req_cnt ==
				     s->wifi_beacon_rx_rel_cnt + s->wifi_beacon_rx_rel_to_cnt,
			     "Wi-Fi beacon_rx: req == rel + rel_to");

	failures += tb_check(&check_num,
			     s->wifi_conn_req_cnt ==
				     s->wifi_conn_gnt_cnt + s->wifi_conn_no_gnt_cnt,
			     "Wi-Fi conn: req == gnt + no_gnt");

	failures += tb_check(&check_num,
			     s->wifi_conn_req_cnt ==
				     s->wifi_conn_rel_cnt + s->wifi_conn_rel_to_cnt,
			     "Wi-Fi conn: req == rel + rel_to");

	failures += tb_check(&check_num,
			     s->wifi_calib_req_cnt ==
				     s->wifi_calib_gnt_cnt + s->wifi_calib_no_gnt_cnt,
			     "Wi-Fi calib: req == gnt + no_gnt");

	failures += tb_check(&check_num,
			     s->wifi_calib_req_cnt ==
				     s->wifi_calib_rel_cnt + s->wifi_calib_rel_to_cnt,
			     "Wi-Fi calib: req == rel + rel_to");

	failures += tb_check(&check_num,
			     s->wifi_scan_req_cnt ==
				     s->wifi_scan_gnt_cnt + s->wifi_scan_no_gnt_cnt,
			     "Wi-Fi scan: req == gnt + no_gnt");

	failures += tb_check(&check_num,
			     s->wifi_scan_req_cnt ==
				     s->wifi_scan_rel_cnt + s->wifi_scan_rel_to_cnt,
			     "Wi-Fi scan: req == rel + rel_to");

	/* Every SR Rx protection attempt either succeeded or failed. */
	failures += tb_check(&check_num,
			     s->sr_rx_prot_2pt4g_band_cnt ==
				     s->sr_rx_prot_success_cnt_2pt4g +
					     s->sr_rx_prot_fail_cnt_2pt4g,
			     "SR Rx prot 2.4G: band == success + fail");

	failures += tb_check(&check_num,
			     s->sr_rx_prot_non2pt4g_band_cnt ==
				     s->sr_rx_prot_success_cnt_non_2pt4g +
					     s->sr_rx_prot_fail_cnt_non_2pt4g,
			     "SR Rx prot non-2.4G: band == success + fail");

	/* ... and was attributed to exactly one of the four protection scenarios. */
	failures += tb_check(&check_num,
			     s->sr_rx_prot_2pt4g_band_cnt ==
				     s->sr_rx_prot_inact2listen_ps_cnt_2pt4g +
					     s->sr_rx_prot_listen2inact_ps_cnt_2pt4g +
					     s->sr_rx_prot_inact2listen_calib_cnt_2pt4g +
					     s->sr_rx_prot_listen2inact_calib_cnt_2pt4g,
			     "SR Rx prot 2.4G: band == sum(scenario counts)");

	failures += tb_check(&check_num,
			     s->sr_rx_prot_non2pt4g_band_cnt ==
				     s->sr_rx_prot_inact2listen_ps_cnt_non_2pt4g +
					     s->sr_rx_prot_listen2inact_ps_cnt_non_2pt4g +
					     s->sr_rx_prot_inact2listen_calib_cnt_non_2pt4g +
					     s->sr_rx_prot_listen2inact_calib_cnt_non_2pt4g,
			     "SR Rx prot non-2.4G: band == sum(scenario counts)");

	/* Each coex-params command reprograms the ANTSWC inhibit/PA/LNA overrides. */
	failures += tb_check(&check_num,
			     s->antswc_inhibit_cfg_cnt == s->cmd_update_coex_params_cnt,
			     "ANTSWC inhibit_cfg == cmd_update_coex_params");

	/* Each user-params command reprograms the antenna override. */
	failures += tb_check(&check_num,
			     s->antswc_anten_override_cfg_cnt == s->cmd_update_user_params_cnt,
			     "ANTSWC anten_override_cfg == cmd_update_user_params");

	failures += tb_check(&check_num,
			     s->antswc_pa_override_cfg_cnt == s->cmd_update_coex_params_cnt,
			     "ANTSWC pa_override_cfg == cmd_update_coex_params");

	failures += tb_check(&check_num,
			     s->antswc_lnasw_override_cfg_cnt == s->cmd_update_coex_params_cnt,
			     "ANTSWC lnasw_override_cfg == cmd_update_coex_params");

	/* Wi-Fi CCCONF is saved before an SR window and restored after it. */
	failures += tb_check(&check_num,
			     s->wifi_ccconf_save_cnt == s->wifi_ccconf_restore_cnt,
			     "Wi-Fi CCCONF save == restore");

	/* Every PPW command was either a start or a stop. */
	failures += tb_check(&check_num,
			     s->cmd_allocate_ppw_cnt ==
				     s->ppw_start_msgs_cnt + s->ppw_stop_msgs_cnt,
			     "cmd_allocate_ppw == ppw_start + ppw_stop");

	printk("\n============ End of Validation: %u checks, %u failed ============\n\n",
	       check_num, failures);

	return failures;
}

unsigned int coex_tb_print_and_validate_stats(const struct cm_stats_t *stats,
					      const struct cm_fsm_patch_stats_t *patch_stats)
{
	unsigned int failures;

	if (stats == NULL) {
		printk("Coex TB stats: no statistics payload to validate\n");
		return 1U;
	}

	coex_tb_print_stats(stats, patch_stats);
	failures = coex_tb_validate_stats(stats);

	if (patch_stats != NULL) {
		coex_tb_print_patch_stats(patch_stats);
	} else {
		/* Unpatched CM firmware: informational, not a failure. */
		printk("\nPatch command counters not available in this CM2CD event payload.\n");
	}

	return failures;
}
```

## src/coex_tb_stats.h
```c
/*
 * Copyright (c) 2026 Nordic Semiconductor ASA
 *
 * SPDX-License-Identifier: LicenseRef-Nordic-5-Clause
 */

/** @file
 * @brief Coexistence Manager (CM) statistics printing and consistency checking.
 *
 * The counters belong to the CM, but they are used here as evidence about the
 * driver: how many commands of each type the driver actually emitted, and how
 * the CM reacted to them. That makes them the closest thing available to an
 * external observation of the driver's outgoing traffic.
 *
 * The CM keeps a large set of counters: how many requests it saw, how
 * many it granted, how many commands of each type arrived, and so on. Reading
 * them back through coex_cd_get_stats() confirms that the commands the driver
 * sent on the bench's behalf arrived and were understood.
 *
 * Two payloads can arrive with a statistics event:
 *   cm_stats_t            - always present, the ROM counters
 *   cm_fsm_patch_stats_t  - only with patched CM firmware, adds per-event counters
 */

#ifndef COEX_TB_STATS_H__
#define COEX_TB_STATS_H__

#include <nrf71_coex_if.h>

/**
 * Print the CM counters and run consistency checks over them.
 *
 * @param stats       ROM counters. NULL is reported as one failure.
 * @param patch_stats Patch counters, or NULL if the firmware did not send them.
 *                    Absence is reported but is not counted as a failure.
 *
 * @return Number of failed checks. Zero means everything was consistent.
 */
unsigned int coex_tb_print_and_validate_stats(const struct cm_stats_t *stats,
					      const struct cm_fsm_patch_stats_t *patch_stats);

#endif /* COEX_TB_STATS_H__ */
```

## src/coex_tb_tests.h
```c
/*
 * Copyright (c) 2026 Nordic Semiconductor ASA
 *
 * SPDX-License-Identifier: LicenseRef-Nordic-5-Clause
 */

/** @file
 * @brief Coexistence driver test steps and the top-level runner.
 */

#ifndef COEX_TB_TESTS_H__
#define COEX_TB_TESTS_H__

/**
 * Run every enabled test step in order, stopping at the first failure.
 *
 * Which steps are enabled is controlled by the COEX_TB_TEST_* macros in
 * coex_tb.h. Steps are ordered deliberately: COEXC programming and argument
 * validation come first, then radio bring-up through the Wi-Fi and SR power
 * notifications, then the runtime commands, then the statistics read-back that
 * confirms which commands the driver actually emitted.
 *
 * @retval 0  All enabled steps passed.
 * @retval <0 The negative errno reported by the first failing step.
 */
int coex_tb_run_all(void);

#endif /* COEX_TB_TESTS_H__ */
```

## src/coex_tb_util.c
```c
/*
 * Copyright (c) 2026 Nordic Semiconductor ASA
 *
 * SPDX-License-Identifier: LicenseRef-Nordic-5-Clause
 */

/** @file
 * @brief Test bench utilities.
 */

#include <errno.h>
#include <stdbool.h>
#include <string.h>

#include <zephyr/devicetree.h>
#include <zephyr/kernel.h>
#include <zephyr/net/net_if.h>
#include <zephyr/sys/printk.h>
#include <zephyr/sys/util.h>

#include <drivers/wifi/nrf71/nrf71_wifi_coex.h>
#include <nrf71_coex_if.h>

#include "coex_tb.h"
#include "coex_tb_util.h"

const char *coex_tb_errstr(int err)
{
	if (err == 0) {
		return "success";
	}

	if (err < 0) {
		return strerror(-err);
	}

	return "positive status code";
}

#ifdef COEX_TB_DUMP_WIFI_BRINGUP_STATE
#define WICR_NODE DT_NODELABEL(wicr)
#define IPC_NODE  DT_NODELABEL(ipc0)

#define WICR_REG(off) (*(volatile uint32_t *)(DT_REG_ADDR(WICR_NODE) + (off)))

/*
 * Must match the magic in subsys/ipc/ipc_service/lib/icmsg.c: each side writes
 * it into its own TX region during endpoint setup and treats the endpoint as
 * bound once it shows up in the RX region.
 */
static const uint8_t icmsg_magic[] = {0x45, 0x6d, 0x31, 0x6c, 0x31, 0x4b,
				      0x30, 0x72, 0x6e, 0x33, 0x6c, 0x69, 0x34};

/* Wide enough to cover the pbuf header that precedes the magic in shared RAM. */
#define ICMSG_MAGIC_SEARCH_LEN 64U
#define REGION_DUMP_LEN        32U

struct wicr_expect {
	const char *name;
	uint16_t offset;
	uint32_t expect;
};

/* Offsets and expected values mirror wicr_words[] in soc/nordic/nrf71/wicr_setup.c. */
static const struct wicr_expect wicr_expected[] = {
	{"LMACINITPC", 0x000, DT_REG_ADDR(DT_PHANDLE(WICR_NODE, firmware_lmacinitpc))},
	{"UMACINITPC", 0x004, DT_REG_ADDR(DT_PHANDLE(WICR_NODE, firmware_umacinitpc))},
	{"LMACPATCH", 0x008, DT_REG_ADDR(DT_PHANDLE(WICR_NODE, firmware_lmacrompatchaddr))},
	{"UMACPATCH", 0x00C, DT_REG_ADDR(DT_PHANDLE(WICR_NODE, firmware_umacrompatchaddr))},
	{"CMDMBOX addr", 0x080, DT_REG_ADDR(DT_PHANDLE(WICR_NODE, ipcconfig_commandmbox))},
	{"CMDMBOX size", 0x084, DT_REG_SIZE(DT_PHANDLE(WICR_NODE, ipcconfig_commandmbox))},
	{"EVTMBOX addr", 0x088, DT_REG_ADDR(DT_PHANDLE(WICR_NODE, ipcconfig_eventmbox))},
	{"EVTMBOX size", 0x08C, DT_REG_SIZE(DT_PHANDLE(WICR_NODE, ipcconfig_eventmbox))},
	{"SPARE addr", 0x090, DT_REG_ADDR(DT_PHANDLE(WICR_NODE, ipcconfig_sparembox))},
	{"SPARE size", 0x094, DT_REG_SIZE(DT_PHANDLE(WICR_NODE, ipcconfig_sparembox))},
};

static bool region_has_icmsg_magic(uintptr_t base)
{
	const volatile uint8_t *region = (const volatile uint8_t *)base;

	for (size_t off = 0U; off + sizeof(icmsg_magic) <= ICMSG_MAGIC_SEARCH_LEN; off++) {
		size_t i;

		for (i = 0U; i < sizeof(icmsg_magic); i++) {
			if (region[off + i] != icmsg_magic[i]) {
				break;
			}
		}

		if (i == sizeof(icmsg_magic)) {
			return true;
		}
	}

	return false;
}

static void dump_region(const char *name, uintptr_t base)
{
	const volatile uint8_t *region = (const volatile uint8_t *)base;

	printk("Coex TB: %s @ 0x%08lx:", name, (unsigned long)base);

	for (size_t i = 0U; i < REGION_DUMP_LEN; i++) {
		printk(" %02x", region[i]);
	}

	printk("\n");
}

void coex_tb_dump_wifi_bringup_state(void)
{
	uintptr_t tx = DT_REG_ADDR(DT_PHANDLE(IPC_NODE, tx_region));
	uintptr_t rx = DT_REG_ADDR(DT_PHANDLE(IPC_NODE, rx_region));

	printk("\n=================== Wi-Fi bring-up state\n");

	for (size_t i = 0U; i < ARRAY_SIZE(wicr_expected); i++) {
		uint32_t actual = WICR_REG(wicr_expected[i].offset);

		printk("Coex TB: WICR 0x%03x %-12s = 0x%08x (expected 0x%08x)%s\n",
		       (unsigned int)wicr_expected[i].offset, wicr_expected[i].name, actual,
		       wicr_expected[i].expect,
		       (actual == wicr_expected[i].expect) ? "" : "   <-- MISMATCH");
	}

	dump_region("ipc0 tx host->UMAC", tx);
	dump_region("ipc0 rx UMAC->host", rx);

	printk("Coex TB: ICMsg magic present: host tx %s, host rx %s\n",
	       region_has_icmsg_magic(tx) ? "yes" : "no",
	       region_has_icmsg_magic(rx) ? "yes" : "no");
}
#endif /* COEX_TB_DUMP_WIFI_BRINGUP_STATE */

/** Poll until the Wi-Fi FMAC coexistence transport reports ready. */
int coex_tb_wait_transport_ready(uint32_t timeout_ms)
{
	uint32_t elapsed_ms = 0U;
	unsigned int stable_polls = 0U;

	while (stable_polls < COEX_TB_TRANSPORT_STABLE_POLLS) {
		if (elapsed_ms >= timeout_ms) {
			printk("Coex TB: transport not ready after %u ms (%s)\n", timeout_ms,
			       coex_tb_errstr(-ETIMEDOUT));
			return -ETIMEDOUT;
		}

		if (nrf71_wifi_coex_is_ready()) {
			stable_polls++;
		} else {
			stable_polls = 0U;
		}

		k_msleep(COEX_TB_POLL_INTERVAL_MS);
		elapsed_ms += COEX_TB_POLL_INTERVAL_MS;
	}

	printk("Coex TB: transport stable after %u ms\n", elapsed_ms);

	return 0;
}

/*
 * Waits for administrative up only. The nRF71 driver marks the interface
 * dormant until a Wi-Fi association, so net_if_is_up() (operational up) stays
 * false for the whole unassociated test run.
 */
static int coex_tb_wait_net_if_up(uint32_t timeout_ms)
{
	uint32_t elapsed_ms = 0U;

	while (elapsed_ms < timeout_ms) {
		struct net_if *iface = net_if_get_default();

		if ((iface != NULL) && net_if_is_admin_up(iface)) {
			printk("Coex TB: network interface admin up after %u ms\n", elapsed_ms);
			return 0;
		}

		k_msleep(COEX_TB_POLL_INTERVAL_MS);
		elapsed_ms += COEX_TB_POLL_INTERVAL_MS;
	}

	printk("Coex TB: network interface not admin up after %u ms (%s)\n", timeout_ms,
	       coex_tb_errstr(-ETIMEDOUT));

	return -ETIMEDOUT;
}

#if defined(COEX_TB_NEEDS_CM_BRINGUP) && !defined(COEX_TB_TEST_INIT_AND_ENABLE)
static int coex_tb_wait_wifi_cm_up(uint32_t timeout_ms)
{
	uint32_t elapsed_ms = 0U;

	while (elapsed_ms < timeout_ms) {
		if (coex_cd_wifi_is_up()) {
			printk("Coex TB: CM bring-up complete after %u ms\n", elapsed_ms);
			return 0;
		}

		k_msleep(COEX_TB_POLL_INTERVAL_MS);
		elapsed_ms += COEX_TB_POLL_INTERVAL_MS;
	}

	return -ETIMEDOUT;
}
#endif /* COEX_TB_NEEDS_CM_BRINGUP && !COEX_TB_TEST_INIT_AND_ENABLE */

/**
 * Wait for transport, let the RPU/VIF settle, and ensure CM bring-up completed.
 */
int coex_tb_prepare(void)
{
	int ret;

	ret = coex_tb_wait_transport_ready(COEX_TB_TRANSPORT_TIMEOUT_MS);
	if (ret != 0) {
		return ret;
	}

	ret = coex_tb_wait_net_if_up(COEX_TB_TRANSPORT_TIMEOUT_MS);
	if (ret != 0) {
		return ret;
	}

	printk("Coex TB: waiting %u ms for RPU/VIF settle\n", COEX_TB_RPU_SETTLE_MS);
	k_msleep(COEX_TB_RPU_SETTLE_MS);

#if defined(COEX_TB_NEEDS_CM_BRINGUP) && !defined(COEX_TB_TEST_INIT_AND_ENABLE)
	ret = coex_tb_wait_wifi_cm_up(COEX_TB_CM_BRINGUP_TIMEOUT_MS);
	if (ret != 0) {
		printk("Coex TB: Wi-Fi driver CM bring-up not done; posting power notify\n");
		ret = coex_cd_wifi_power_notify(COEX_WIFI_POWERED_UP_READY);
		if (ret != 0) {
			printk("Coex TB: Wi-Fi power notify failed: %s (%d)\n", coex_tb_errstr(ret),
			       ret);
			return ret;
		}
	}

	if (!coex_cd_wifi_is_up()) {
		printk("Coex TB: CM bring-up finished but wifi_up is still false (%s)\n",
		       coex_tb_errstr(-EIO));
		return -EIO;
	}
#endif /* COEX_TB_NEEDS_CM_BRINGUP && !COEX_TB_TEST_INIT_AND_ENABLE */

	return 0;
}

/** Sleep for the requested interval between test steps. */
void coex_tb_wait_ms(uint32_t wait_ms)
{
	k_msleep(wait_ms);
}
```
